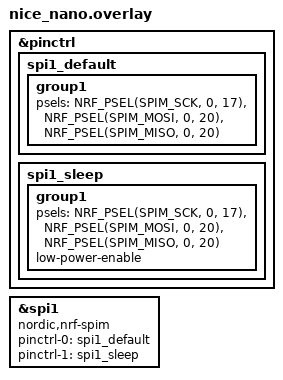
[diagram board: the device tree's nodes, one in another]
#include <dt-bindings/zmk/input_transform.h>

&pinctrl {
    spi1_default: spi1_default {
        group1 {
            psels
              = <NRF_PSEL(SPIM_SCK, 0, 17)>
              , <NRF_PSEL(SPIM_MOSI, 0, 20)>
              , <NRF_PSEL(SPIM_MISO, 0, 20)>
              ;
        };
    };

    spi1_sleep: spi1_sleep {
        group1 {
            psels
              = <NRF_PSEL(SPIM_SCK, 0, 17)>
              , <NRF_PSEL(SPIM_MOSI, 0, 20)>
              , <NRF_PSEL(SPIM_MISO, 0, 20)>
              ;
            low-power-enable;
        };
    };
};


&spi1 {
  status = "okay";
  compatible = "nordic,nrf-spim";
  pinctrl-0 = <&spi1_default>;
  pinctrl-1 = <&spi1_sleep>;
  pinctrl-names = "default", "sleep";
};
